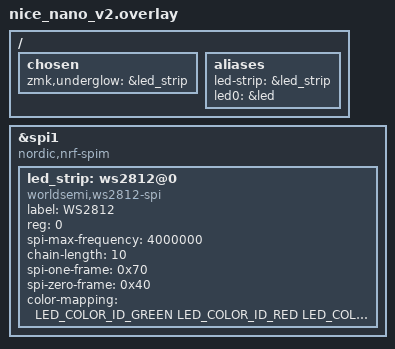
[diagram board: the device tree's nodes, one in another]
/*
 * Copyright (c) 2020 The ZMK Contributors
 *
 * SPDX-License-Identifier: MIT
 */

#include <dt-bindings/led/led.h>

/ {
	chosen {
		zmk,underglow = &led_strip;
	};
};

&spi1 {
	compatible = "nordic,nrf-spim";
	led_strip: ws2812@0 {
		compatible = "worldsemi,ws2812-spi";
		label = "WS2812";

		/* SPI */
		reg = <0>; /* ignored, but necessary for SPI bindings */
		spi-max-frequency = <4000000>;

		/* WS2812 */
		chain-length = <10>; /* number of LEDs */
		spi-one-frame = <0x70>;
		spi-zero-frame = <0x40>;
		color-mapping = <LED_COLOR_ID_GREEN LED_COLOR_ID_RED LED_COLOR_ID_BLUE>;
	};
};

/ {
	aliases {
		led-strip = &led_strip;
		led0 = &led;
	};
};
